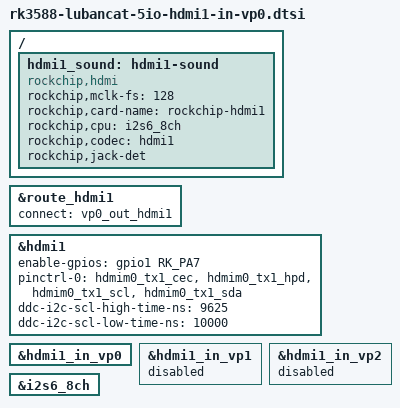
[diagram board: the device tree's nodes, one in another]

/ {
	hdmi1_sound: hdmi1-sound {
		status = "okay";
		compatible = "rockchip,hdmi";
		rockchip,mclk-fs = <128>;
		rockchip,card-name = "rockchip-hdmi1";
		rockchip,cpu = <&i2s6_8ch>;
		rockchip,codec = <&hdmi1>;
		rockchip,jack-det;
	};
};

&route_hdmi1{
	status = "okay";
	connect = <&vp0_out_hdmi1>;
};

&hdmi1 {
	enable-gpios = <&gpio1 RK_PA7 GPIO_ACTIVE_HIGH>;
	pinctrl-0 = <&hdmim0_tx1_cec &hdmim0_tx1_hpd &hdmim0_tx1_scl &hdmim0_tx1_sda>;
	ddc-i2c-scl-high-time-ns = <9625>;
	ddc-i2c-scl-low-time-ns = <10000>;
	pinctrl-names = "default";
	status = "okay";
};

&hdmi1_in_vp0 {
	status = "okay";
};

&hdmi1_in_vp1 {
	status = "disabled";
};

&hdmi1_in_vp2 {
	status = "disabled";
};

&i2s6_8ch {
	status = "okay";
};
